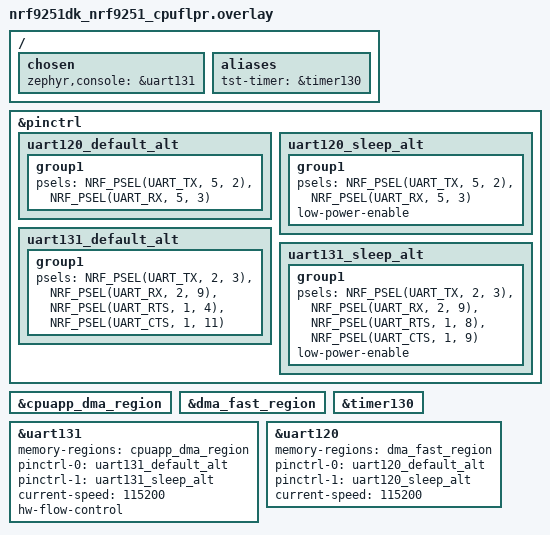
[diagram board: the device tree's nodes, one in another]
/*
 * Copyright (c) 2026 Nordic Semiconductor ASA
 *
 * SPDX-License-Identifier: LicenseRef-Nordic-5-Clause
 */

/ {
	chosen {
		zephyr,console = &uart131;
	};

	aliases {
		tst-timer = &timer130;
	};
};

/* UART device used for test
 * not the default UART assignment for the LD
 */
&pinctrl {
	uart120_default_alt: uart120_default_alt {
		group1 {
			psels = <NRF_PSEL(UART_TX, 5, 2)>,
				<NRF_PSEL(UART_RX, 5, 3)>;
		};
	};

	uart120_sleep_alt: uart120_sleep_alt {
		group1 {
			psels = <NRF_PSEL(UART_TX, 5, 2)>,
				<NRF_PSEL(UART_RX, 5, 3)>;
			low-power-enable;
		};
	};

	uart131_default_alt: uart131_default_alt {
		group1 {
			psels = <NRF_PSEL(UART_TX, 2, 3)>,
				<NRF_PSEL(UART_RX, 2, 9)>,
				<NRF_PSEL(UART_RTS, 1, 4)>,
				<NRF_PSEL(UART_CTS, 1, 11)>;
		};
	};

	uart131_sleep_alt: uart131_sleep_alt {
		group1 {
			psels = <NRF_PSEL(UART_TX, 2, 3)>,
				<NRF_PSEL(UART_RX, 2, 9)>,
				<NRF_PSEL(UART_RTS, 1, 8)>,
				<NRF_PSEL(UART_CTS, 1, 9)>;
			low-power-enable;
		};
	};
};

&cpuapp_dma_region {
	status = "okay";
};

&dma_fast_region {
	status = "okay";
};

&timer130 {
	status = "okay";
};

&uart131 {
	status = "okay";
	memory-regions = <&cpuapp_dma_region>;
	pinctrl-0 = <&uart131_default_alt>;
	pinctrl-1 = <&uart131_sleep_alt>;
	pinctrl-names = "default", "sleep";
	current-speed = <115200>;
	hw-flow-control;
};

dut: &uart120 {
	status = "okay";
	memory-regions = <&dma_fast_region>;
	pinctrl-0 = <&uart120_default_alt>;
	pinctrl-1 = <&uart120_sleep_alt>;
	pinctrl-names = "default", "sleep";
	current-speed = <115200>;
	/delete-property/ hw-flow-control;
};
